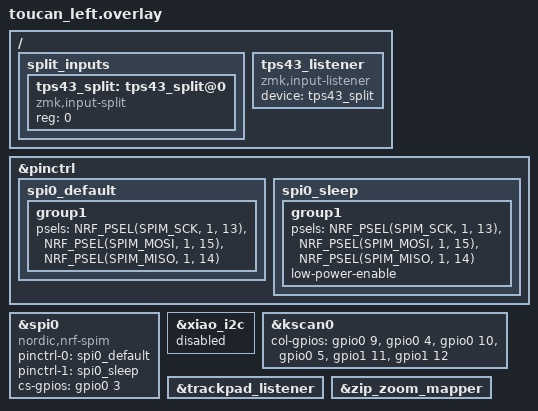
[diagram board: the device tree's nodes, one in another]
#include "toucan.dtsi"

&pinctrl {
    spi0_default: spi0_default {
        group1 {
            psels = <NRF_PSEL(SPIM_SCK, 1, 13)>,
                <NRF_PSEL(SPIM_MOSI, 1, 15)>,
                <NRF_PSEL(SPIM_MISO, 1, 14)>;
        };
    };

     spi0_sleep: spi0_sleep {
        group1 {
            psels = <NRF_PSEL(SPIM_SCK, 1, 13)>,
                    <NRF_PSEL(SPIM_MOSI, 1, 15)>,
                    <NRF_PSEL(SPIM_MISO, 1, 14)>;
            low-power-enable;
        };
    };

};

nice_view_spi: &spi0 {
   compatible = "nordic,nrf-spim";
   pinctrl-0 = <&spi0_default>;
   pinctrl-1 = <&spi0_sleep>;
   pinctrl-names = "default", "sleep";
   cs-gpios = <&gpio0 3 GPIO_ACTIVE_HIGH>;
};

&xiao_i2c {
    status = "disabled";
};

&kscan0 {
    col-gpios
    = <&gpio0 9 GPIO_ACTIVE_HIGH>
    , <&gpio0 4 GPIO_ACTIVE_HIGH>
    , <&gpio0 10 GPIO_ACTIVE_HIGH>
    , <&gpio0 5 GPIO_ACTIVE_HIGH>
    , <&gpio1 11 GPIO_ACTIVE_HIGH>
    , <&gpio1 12 GPIO_ACTIVE_HIGH>
    ;
};

&trackpad_listener {
    status = "okay";
};

&zip_zoom_mapper {
    status = "okay";
};

/ {
    split_inputs {
        #address-cells = <1>;
        #size-cells = <0>;

        tps43_split: tps43_split@0 {
            compatible = "zmk,input-split";
            reg = <0>;
            /* No device property here - this is a proxy on the central side */
        };
    };

    tps43_listener: tps43_listener {
        compatible = "zmk,input-listener";
        device = <&tps43_split>;
        status = "okay";
    };
};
